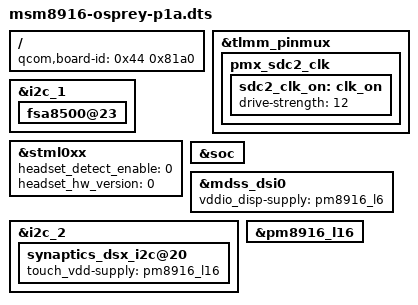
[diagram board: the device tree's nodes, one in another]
/* Copyright (c) 2014, Motorola Mobility LLC. All rights reserved.
*
* This program is free software; you can redistribute it and/or modify
* it under the terms of the GNU General Public License version 2 and
* only version 2 as published by the Free Software Foundation.
*
* This program is distributed in the hope that it will be useful,
* but WITHOUT ANY WARRANTY; without even the implied warranty of
* MERCHANTABILITY or FITNESS FOR A PARTICULAR PURPOSE.  See the
* GNU General Public License for more details.
*/

/dts-v1/;

#include "msm8916-osprey.dtsi"

/ {
	qcom,board-id = <0x44 0x81a0>;
};

&tlmm_pinmux {
	pmx_sdc2_clk {
		sdc2_clk_on: clk_on {
			drive-strength = <12>; /* 12 MA */
		};
	};
};

&i2c_1 {
	fsa8500@23 {
		status = "ok";
	};
};

&stml0xx {
		headset_detect_enable = <0>;
		headset_hw_version = <0>;
};

&soc {
	/delete-node/ vddio_disp_vreg;
	/delete-node/ vdda_touch_vreg;
};

&mdss_dsi0 {
	vddio_disp-supply = <&pm8916_l6>;
};

&i2c_2 {
	synaptics_dsx_i2c@20 {
		touch_vdd-supply = <&pm8916_l16>;
	};
};

&pm8916_l16 {
	/delete-property/ regulator-boot-on;
	/delete-property/ regulator-always-on;
};
